# HDSC_HC32M423 register map
Vendor: HDSC Co.,Ltd.; Series: ARMCM4; File version: 1.0
CPU: CM4 r0p1, little endian, MPU, FPU, 4 interrupt priority bits
Registers are 32-bit, read-write, reset 0x0 unless marked. A register's access mark holds for its fields unless they carry their own. Offsets are from the block's base; [hi:lo] are bit positions.

## TMR4
Base 0x40017000
0x02 OCCRUH 16-bit
0x06 OCCRUL 16-bit
0x0A OCCRVH 16-bit
0x0E OCCRVL 16-bit
0x12 OCCRWH 16-bit
0x16 OCCRWL 16-bit
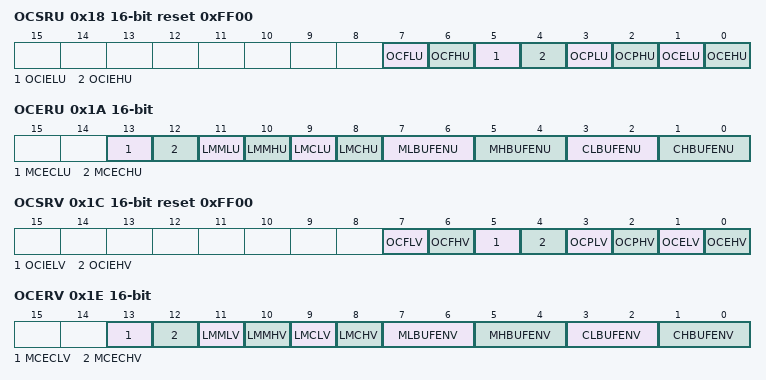
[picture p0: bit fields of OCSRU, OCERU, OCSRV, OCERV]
0x18 OCSRU 16-bit reset 0xFF00
  [7] OCFLU, [6] OCFHU, [5] OCIELU, [4] OCIEHU, [3] OCPLU, [2] OCPHU, [1] OCELU, [0] OCEHU
0x1A OCERU 16-bit
  [13] MCECLU, [12] MCECHU, [11] LMMLU, [10] LMMHU, [9] LMCLU, [8] LMCHU, [7:6] MLBUFENU, [5:4] MHBUFENU, [3:2] CLBUFENU, [1:0] CHBUFENU
0x1C OCSRV 16-bit reset 0xFF00
  [7] OCFLV, [6] OCFHV, [5] OCIELV, [4] OCIEHV, [3] OCPLV, [2] OCPHV, [1] OCELV, [0] OCEHV
0x1E OCERV 16-bit
  [13] MCECLV, [12] MCECHV, [11] LMMLV, [10] LMMHV, [9] LMCLV, [8] LMCHV, [7:6] MLBUFENV, [5:4] MHBUFENV, [3:2] CLBUFENV, [1:0] CHBUFENV
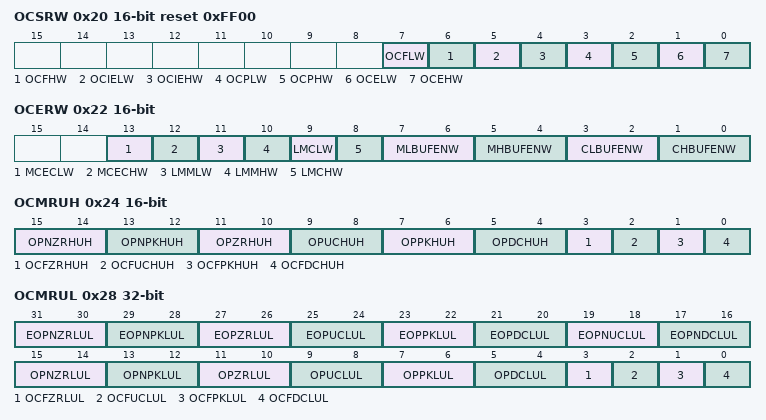
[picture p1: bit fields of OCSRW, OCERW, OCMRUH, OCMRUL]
0x20 OCSRW 16-bit reset 0xFF00
  [7] OCFLW, [6] OCFHW, [5] OCIELW, [4] OCIEHW, [3] OCPLW, [2] OCPHW, [1] OCELW, [0] OCEHW
0x22 OCERW 16-bit
  [13] MCECLW, [12] MCECHW, [11] LMMLW, [10] LMMHW, [9] LMCLW, [8] LMCHW, [7:6] MLBUFENW, [5:4] MHBUFENW, [3:2] CLBUFENW, [1:0] CHBUFENW
0x24 OCMRUH 16-bit
  [15:14] OPNZRHUH, [13:12] OPNPKHUH, [11:10] OPZRHUH, [9:8] OPUCHUH, [7:6] OPPKHUH, [5:4] OPDCHUH, [3] OCFZRHUH, [2] OCFUCHUH, [1] OCFPKHUH, [0] OCFDCHUH
0x28 OCMRUL
  [31:30] EOPNZRLUL, [29:28] EOPNPKLUL, [27:26] EOPZRLUL, [25:24] EOPUCLUL, [23:22] EOPPKLUL, [21:20] EOPDCLUL, [19:18] EOPNUCLUL, [17:16] EOPNDCLUL, [15:14] OPNZRLUL, [13:12] OPNPKLUL, [11:10] OPZRLUL, [9:8] OPUCLUL, [7:6] OPPKLUL, [5:4] OPDCLUL, [3] OCFZRLUL, [2] OCFUCLUL, [1] OCFPKLUL, [0] OCFDCLUL
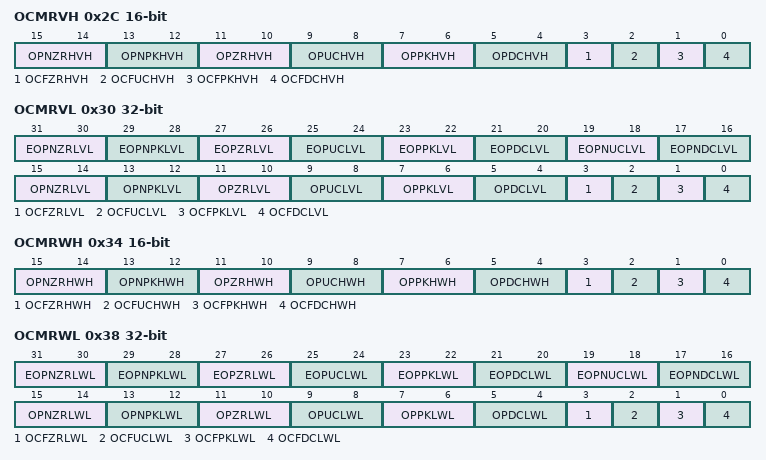
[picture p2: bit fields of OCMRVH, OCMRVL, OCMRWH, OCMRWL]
0x2C OCMRVH 16-bit
  [15:14] OPNZRHVH, [13:12] OPNPKHVH, [11:10] OPZRHVH, [9:8] OPUCHVH, [7:6] OPPKHVH, [5:4] OPDCHVH, [3] OCFZRHVH, [2] OCFUCHVH, [1] OCFPKHVH, [0] OCFDCHVH
0x30 OCMRVL
  [31:30] EOPNZRLVL, [29:28] EOPNPKLVL, [27:26] EOPZRLVL, [25:24] EOPUCLVL, [23:22] EOPPKLVL, [21:20] EOPDCLVL, [19:18] EOPNUCLVL, [17:16] EOPNDCLVL, [15:14] OPNZRLVL, [13:12] OPNPKLVL, [11:10] OPZRLVL, [9:8] OPUCLVL, [7:6] OPPKLVL, [5:4] OPDCLVL, [3] OCFZRLVL, [2] OCFUCLVL, [1] OCFPKLVL, [0] OCFDCLVL
0x34 OCMRWH 16-bit
  [15:14] OPNZRHWH, [13:12] OPNPKHWH, [11:10] OPZRHWH, [9:8] OPUCHWH, [7:6] OPPKHWH, [5:4] OPDCHWH, [3] OCFZRHWH, [2] OCFUCHWH, [1] OCFPKHWH, [0] OCFDCHWH
0x38 OCMRWL
  [31:30] EOPNZRLWL, [29:28] EOPNPKLWL, [27:26] EOPZRLWL, [25:24] EOPUCLWL, [23:22] EOPPKLWL, [21:20] EOPDCLWL, [19:18] EOPNUCLWL, [17:16] EOPNDCLWL, [15:14] OPNZRLWL, [13:12] OPNPKLWL, [11:10] OPZRLWL, [9:8] OPUCLWL, [7:6] OPPKLWL, [5:4] OPDCLWL, [3] OCFZRLWL, [2] OCFUCLWL, [1] OCFPKLWL, [0] OCFDCLWL
0x42 CPSR 16-bit reset 0xFFFF
0x46 CNTR 16-bit
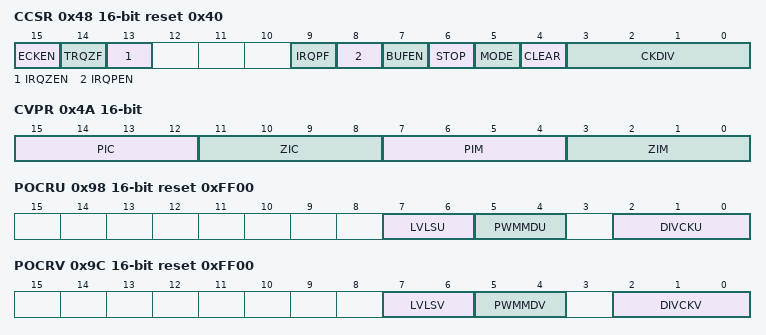
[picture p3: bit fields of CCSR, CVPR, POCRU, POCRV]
0x48 CCSR 16-bit reset 0x40
  [15] ECKEN, [14] TRQZF, [13] IRQZEN, [9] IRQPF, [8] IRQPEN, [7] BUFEN, [6] STOP, [5] MODE, [4] CLEAR, [3:0] CKDIV
0x4A CVPR 16-bit
  [15:12] PIC ro, [11:8] ZIC ro, [7:4] PIM, [3:0] ZIM
0x82 PFSRU 16-bit
0x84 PDARU 16-bit
0x86 PDBRU 16-bit
0x8A PFSRV 16-bit
0x8C PDARV 16-bit
0x8E PDBRV 16-bit
0x92 PFSRW 16-bit
0x94 PDARW 16-bit
0x96 PDBRW 16-bit
0x98 POCRU 16-bit reset 0xFF00
  [7:6] LVLSU, [5:4] PWMMDU, [2:0] DIVCKU
0x9C POCRV 16-bit reset 0xFF00
  [7:6] LVLSV, [5:4] PWMMDV, [2:0] DIVCKV
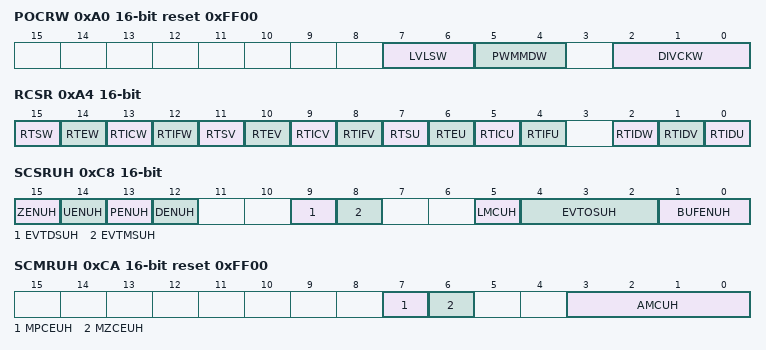
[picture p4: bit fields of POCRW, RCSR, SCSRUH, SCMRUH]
0xA0 POCRW 16-bit reset 0xFF00
  [7:6] LVLSW, [5:4] PWMMDW, [2:0] DIVCKW
0xA4 RCSR 16-bit
  [15] RTSW, [14] RTEW, [13] RTICW, [12] RTIFW ro, [11] RTSV, [10] RTEV, [9] RTICV, [8] RTIFV ro, [7] RTSU, [6] RTEU, [5] RTICU, [4] RTIFU ro, [2] RTIDW, [1] RTIDV, [0] RTIDU
0xB2 SCCRUH 16-bit
0xB6 SCCRUL 16-bit
0xBA SCCRVH 16-bit
0xBE SCCRVL 16-bit
0xC2 SCCRWH 16-bit
0xC6 SCCRWL 16-bit
0xC8 SCSRUH 16-bit
  [15] ZENUH, [14] UENUH, [13] PENUH, [12] DENUH, [9] EVTDSUH, [8] EVTMSUH, [5] LMCUH, [4:2] EVTOSUH, [1:0] BUFENUH
0xCA SCMRUH 16-bit reset 0xFF00
  [7] MPCEUH, [6] MZCEUH, [3:0] AMCUH
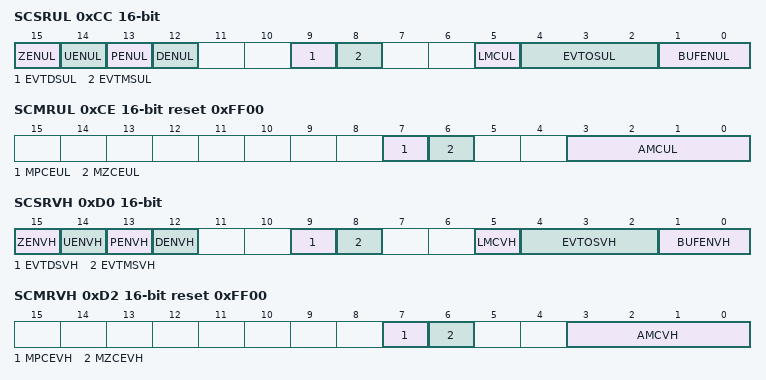
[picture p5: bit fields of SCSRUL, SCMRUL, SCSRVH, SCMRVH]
0xCC SCSRUL 16-bit
  [15] ZENUL, [14] UENUL, [13] PENUL, [12] DENUL, [9] EVTDSUL, [8] EVTMSUL, [5] LMCUL, [4:2] EVTOSUL, [1:0] BUFENUL
0xCE SCMRUL 16-bit reset 0xFF00
  [7] MPCEUL, [6] MZCEUL, [3:0] AMCUL
0xD0 SCSRVH 16-bit
  [15] ZENVH, [14] UENVH, [13] PENVH, [12] DENVH, [9] EVTDSVH, [8] EVTMSVH, [5] LMCVH, [4:2] EVTOSVH, [1:0] BUFENVH
0xD2 SCMRVH 16-bit reset 0xFF00
  [7] MPCEVH, [6] MZCEVH, [3:0] AMCVH
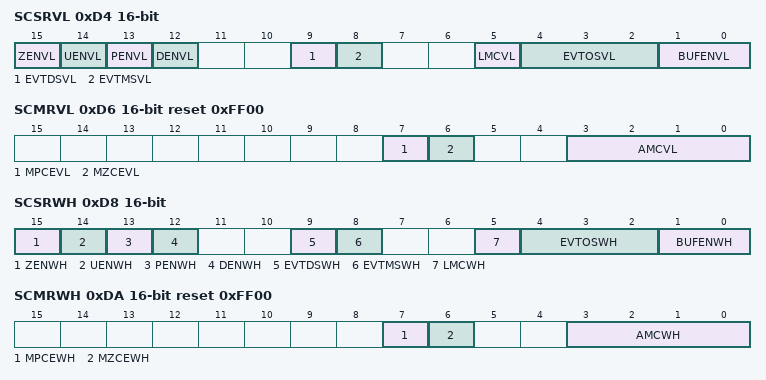
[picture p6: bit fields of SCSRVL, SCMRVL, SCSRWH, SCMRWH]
0xD4 SCSRVL 16-bit
  [15] ZENVL, [14] UENVL, [13] PENVL, [12] DENVL, [9] EVTDSVL, [8] EVTMSVL, [5] LMCVL, [4:2] EVTOSVL, [1:0] BUFENVL
0xD6 SCMRVL 16-bit reset 0xFF00
  [7] MPCEVL, [6] MZCEVL, [3:0] AMCVL
0xD8 SCSRWH 16-bit
  [15] ZENWH, [14] UENWH, [13] PENWH, [12] DENWH, [9] EVTDSWH, [8] EVTMSWH, [5] LMCWH, [4:2] EVTOSWH, [1:0] BUFENWH
0xDA SCMRWH 16-bit reset 0xFF00
  [7] MPCEWH, [6] MZCEWH, [3:0] AMCWH
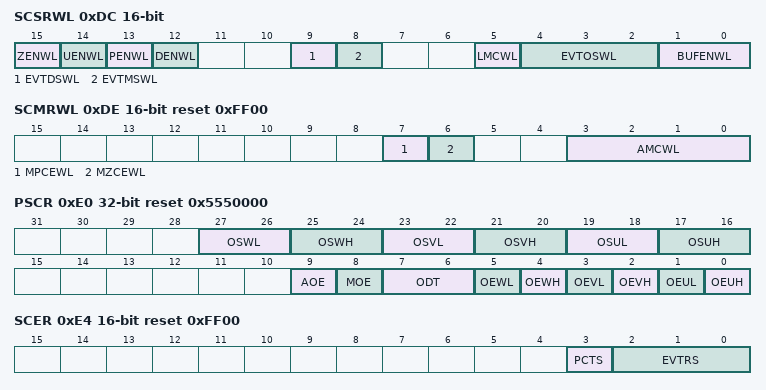
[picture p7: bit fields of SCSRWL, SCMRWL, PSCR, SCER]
0xDC SCSRWL 16-bit
  [15] ZENWL, [14] UENWL, [13] PENWL, [12] DENWL, [9] EVTDSWL, [8] EVTMSWL, [5] LMCWL, [4:2] EVTOSWL, [1:0] BUFENWL
0xDE SCMRWL 16-bit reset 0xFF00
  [7] MPCEWL, [6] MZCEWL, [3:0] AMCWL
0xE0 PSCR reset 0x5550000
  [27:26] OSWL, [25:24] OSWH, [23:22] OSVL, [21:20] OSVH, [19:18] OSUL, [17:16] OSUH, [9] AOE, [8] MOE, [7:6] ODT, [5] OEWL, [4] OEWH, [3] OEVL, [2] OEVH, [1] OEUL, [0] OEUH
0xE4 SCER 16-bit reset 0xFF00
  [3] PCTS, [2:0] EVTRS
